# STM32MP13xx register map
File version: 1.5
CPU: CA7 r0p0, little endian, MPU, FPU, 4 interrupt priority bits
Registers are 32-bit, read-write, reset 0x0 unless marked. A register's access mark holds for its fields unless they carry their own. Offsets are from the block's base; [hi:lo] are bit positions; lines under a group give offsets from that group; 'fields as' and 'values as' point back to an identical list.

## GICC — GICC address block description
Base 0xA0022000
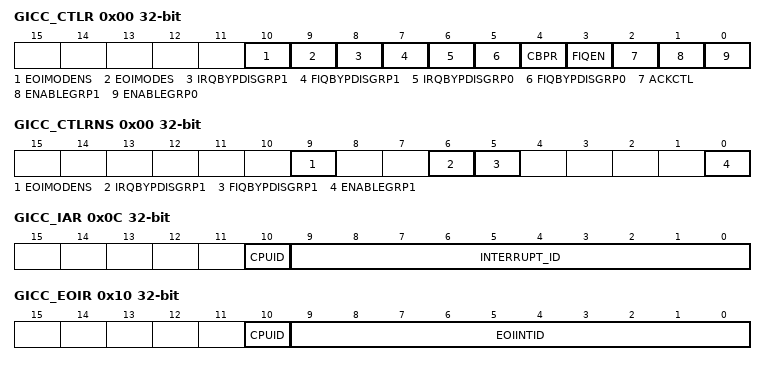
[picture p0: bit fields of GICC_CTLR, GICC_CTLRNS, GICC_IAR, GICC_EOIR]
0x00 GICC_CTLR — GICC control register
  [10] EOIMODENS — Alias of EOIMODENS from the non-secure copy of this register.
  [9] EOIMODES — EOI mode for secure accesses Controls the behavior of accesses to GICC_EOIR and GICC_DIR registers. This control applies only to secure accesses.
  [8] IRQBYPDISGRP1 — Alias of IRQBYPDISGRP1 from the non-secure copy of this register.
  [7] FIQBYPDISGRP1 — Alias of FIQBYPDISGRP1 from the non-secure copy of this register.
  [6] IRQBYPDISGRP0 — IRQ bypass disable for group 0 interrupts When the signaling of IRQs by the CPU interface is disabled, this bit partly controls whether the bypass IRQ signal is signaled to the processor.
  [5] FIQBYPDISGRP0 — FIQ bypass disable for group 0 interrupts When the signaling of FIQs by the CPU interface is disabled, this bit partly controls whether the bypass FIQ signal is signaled to the processor.
  [4] CBPR — BPR control Controls whether the GICC_BPR provides common control to group 0 and group 1 interrupts.
  [3] FIQEN — FIQ enable for group 0 interrupts Controls whether the CPU interface signals group 0 interrupts to a target processor using the FIQ or the IRQ signal. The GIC always signals group 1 interrupts using the IRQ signal.
  [2] ACKCTL — Acknowledge control When the highest priority pending interrupt is a group 1 interrupt, this bit determines both: - whether a read of GICC_IAR acknowledges the interrupt, or returns a spurious interrupt ID - whether a read of GICC_HPPIR returns the ID of the highest priority pending interrupt, or returns a spurious interrupt ID. Arm deprecates use of this bit and strongly recommends using a software model where this bit is set to 0.
  [1] ENABLEGRP1 — Enable group 1 interrupts It enables for the signaling of group 1 interrupts by the CPU interface to the connected processor.
  [0] ENABLEGRP0 — Enable group 0 interrupts It enables for the signaling of group 0interrupts by the CPU interface to the connected processor.
0x00 GICC_CTLRNS (alternate view of GICC_CTLR) — GICC control register
  [9] EOIMODENS — EOI mode for non- secure accesses
  [6] IRQBYPDISGRP1
  [5] FIQBYPDISGRP1
  [0] ENABLEGRP1
0x04 GICC_PMR — GICC input priority mask register
  [7:3] PRIORITY — priority mask level for the CPU interface If the priority of an interrupt is higher than the value indicated by this field, the interface signals the interrupt to the processor.
0x08 GICC_BPR — GICC binary point register
  [2:0] BINARY_POINT — The value of this field controls how the 8-bit interrupt priority field is split into a group priority field. It is used to determine interrupt preemption and a sub-priority field. Minimum value is 2.
0x08 GICC_BPRNS (alternate view of GICC_BPR)
  fields as GICC_BPR
0x0C GICC_IAR ro — GICC interrupt acknowledge register
  [10] CPUID — For SGIs in a multiprocessor implementation, this field identifies the processor that requested the interrupt. It returns the number of the CPU interface that made the request. For example, a value of 1 means the request was generated by a write to the GICD_SGIR on CPU interface 1.
  [9:0] INTERRUPT_ID — The interrupt ID
0x10 GICC_EOIR wo reset not defined
  [10] CPUID — On a multiprocessor implementation, if the write refers to an SGI, this field contains the CPUID value from the corresponding GICC_IAR access.
  [9:0] EOIINTID — It contains the interrupt ID value from the corresponding GICC_IAR access.
0x14 GICC_RPR ro — GICC running priority register
  [7:3] PRIORITY — current running priority on the CPU interface
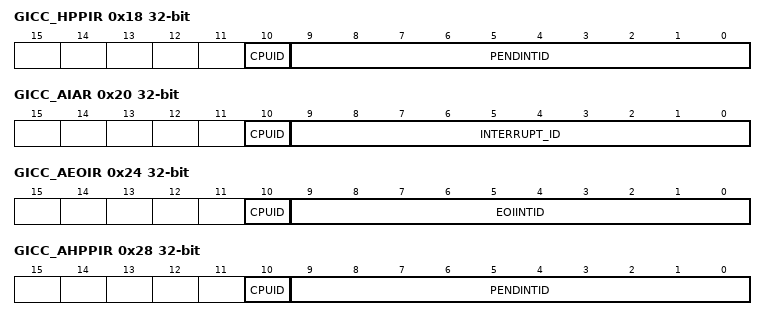
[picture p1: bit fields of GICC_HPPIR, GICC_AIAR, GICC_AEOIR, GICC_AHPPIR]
0x18 GICC_HPPIR ro — GICC highest priority pending interrupt register
  [10] CPUID — On a multiprocessor implementation, if the PENDINTID field returns the ID of an SGI, this field contains the CPUID value for that interrupt. This identifies the processor that generated the interrupt.
  [9:0] PENDINTID — interrupt ID of the highest-priority pending interrupt
0x1C GICC_ABPR — GICC aliased binary point register
  [2:0] BINARY_POINT — The value of this field controls how the 8-bit interrupt priority field is split into a group priority field. It is used to determine interrupt preemption, and a subpriority field. Minimun value is 3.
0x20 GICC_AIAR ro — GICC aliased interrupt acknowledge register
  [10] CPUID — For SGIs in a multiprocessor implementation, this field identifies the processor that requested the interrupt. It returns the number of the CPU interface that made the request. For example, a value of 1 means the request was generated by a write to the GICD_SGIR on CPU interface 1.
  [9:0] INTERRUPT_ID
0x24 GICC_AEOIR wo reset not defined — GICC aliased end of interrupt register
  [10] CPUID — On a multiprocessor implementation, when processing an SGI, this field must contain the CPUID value from the corresponding GICC_AIAR, or non-secure GICC_IAR, access.
  [9:0] EOIINTID — It contains the interrupt ID value from the corresponding GICC_AIAR, or non-secure GICC_IAR, access.
0x28 GICC_AHPPIR ro — GICC aliased highest priority pending interrupt register
  [10] CPUID — On a multiprocessor implementation, if the PENDINTID field returns the ID of an SGI, this field contains the CPUID value for that interrupt. This identifies the processor that generated the interrupt.
  [9:0] PENDINTID — interrupt ID of the highest-priority pending interrupt It contains the interrupt ID of the highest-priority pending interrupt If that interrupt is a group 1 interrupt. Otherwise, its value is the spurious interrupt ID, 1023.
0xD0 GICC_APR0
  [31:0] APR0 — active priority
0xE0 GICC_NSAPR0
  [31:0] NSAPR0 — non-secure active priority
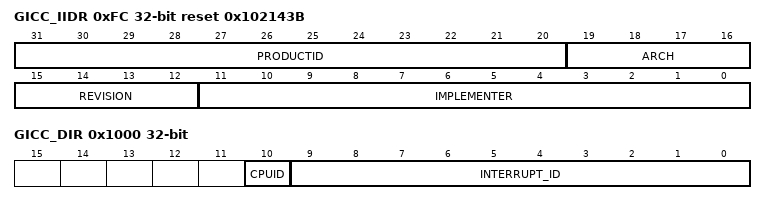
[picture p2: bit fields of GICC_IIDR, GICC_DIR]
0xFC GICC_IIDR ro reset 0x102143B
  [31:20] PRODUCTID
  [19:16] ARCH — architecture version of the GIC
  [15:12] REVISION — revision number for the CPU interface
  [11:0] IMPLEMENTER — GIC implementer (0x43B Arm implementation)
0x1000 GICC_DIR wo reset not defined
  [10] CPUID — CPU ID For an SGI in a multiprocessor implementation, this field identifies the processor that requested the interrupt
  [9:0] INTERRUPT_ID
